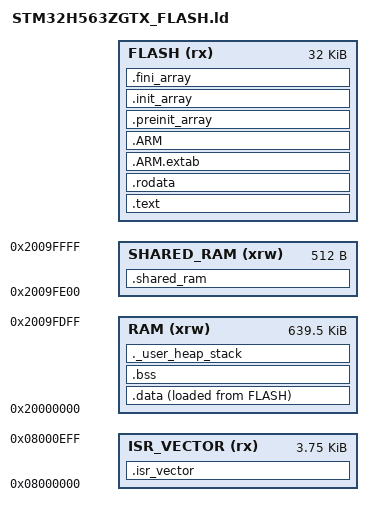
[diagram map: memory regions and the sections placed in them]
/*
******************************************************************************
**
** @file        : LinkerScript.ld
**
** @author      : Auto-generated by STM32CubeIDE
**
** @brief       : Linker script for STM32H563ZGTx Device from STM32H5 series
**                      1024KBytes FLASH
**                      640KBytes RAM
**
**                Set heap size, stack size and stack location according
**                to application requirements.
**
**                Set memory bank area and size if external memory is used
**
**  Target      : STMicroelectronics STM32
**
**  Distribution: The file is distributed as is, without any warranty
**                of any kind.
**
******************************************************************************
** @attention
**
** Copyright (c) 2025 STMicroelectronics.
** All rights reserved.
**
** This software is licensed under terms that can be found in the LICENSE file
** in the root directory of this software component.
** If no LICENSE file comes with this software, it is provided AS-IS.
**
******************************************************************************
*/

/* Entry Point */
ENTRY(Reset_Handler)

/* Highest address of the user mode stack */
_estack = ORIGIN(RAM) + LENGTH(RAM); /* end of "RAM" Ram type memory */

_Min_Heap_Size = 0x200; /* required amount of heap */
_Min_Stack_Size = 0x400; /* required amount of stack */

SECTOR_SIZE              = 0x2000;		/* 8 kB */
FLASH_MEM_SIZE           = 0x100000;	/* 1 MB */
BOOTLOADER_SIZE          = 0x00008000; 	/* 32 kB */
FLASH_BASE             	 = 0x08000000;

BOOTLOADER_START_ADDR   = FLASH_BASE + (FLASH_MEM_SIZE - BOOTLOADER_SIZE);    /* At the end of the memory */

FREE_SPACE_START        = SECTOR_SIZE;        /* The begininning of the free space */
FREE_SPACE_SIZE         = BOOTLOADER_START_ADDR - FREE_SPACE_START;   /* Size of the Free space */

RAM_BASE           = 0x20000000;
RAM_TOTAL_SIZE     = 0xA0000;      /* 640 KB */
SHARED_RAM_SIZE    = 0x200;        /* 512 B */
RAM_MAIN_SIZE      = RAM_TOTAL_SIZE - SHARED_RAM_SIZE;

PROVIDE(__free_space_start = FREE_SPACE_START);
PROVIDE(__free_space_size = FREE_SPACE_SIZE);
PROVIDE(__sector_size = SECTOR_SIZE);

/* Memories definition */
MEMORY
{
  ISR_VECTOR  (rx)   : ORIGIN = FLASH_BASE, LENGTH = 0x00000F00
  RAM         (xrw)  : ORIGIN = RAM_BASE, LENGTH = RAM_MAIN_SIZE
  SHARED_RAM  (xrw)  : ORIGIN = RAM_BASE + RAM_MAIN_SIZE, LENGTH = SHARED_RAM_SIZE
  FLASH    (rx)    	: ORIGIN = BOOTLOADER_START_ADDR,   LENGTH = BOOTLOADER_SIZE
}
/* Sections */
SECTIONS
{

  /* The startup code into "FLASH" Rom type memory */
  .isr_vector :
  {
    . = ALIGN(4);
    KEEP(*(.isr_vector)) /* Startup code */
    . = ALIGN(4);
  } >ISR_VECTOR

  /* The program code and other data into "FLASH" Rom type memory */
  .text :
  {
    . = ALIGN(4);
    *(.text)           /* .text sections (code) */
    *(.text*)          /* .text* sections (code) */
    *(.glue_7)         /* glue arm to thumb code */
    *(.glue_7t)        /* glue thumb to arm code */
    *(.eh_frame)

    KEEP (*(.init))
    KEEP (*(.fini))

    . = ALIGN(4);
    _etext = .;        /* define a global symbols at end of code */
  } >FLASH

  /* Constant data into "FLASH" Rom type memory */
  .rodata :
  {
    . = ALIGN(4);
    *(.rodata)         /* .rodata sections (constants, strings, etc.) */
    *(.rodata*)        /* .rodata* sections (constants, strings, etc.) */
    . = ALIGN(4);
  } >FLASH

  .ARM.extab (READONLY) : /* The "READONLY" keyword is only supported in GCC11 and later, remove it if using GCC10 or earlier. */
  {
    . = ALIGN(4);
    *(.ARM.extab* .gnu.linkonce.armextab.*)
    . = ALIGN(4);
  } >FLASH

  .ARM (READONLY) : /* The "READONLY" keyword is only supported in GCC11 and later, remove it if using GCC10 or earlier. */
  {
    . = ALIGN(4);
    __exidx_start = .;
    *(.ARM.exidx*)
    __exidx_end = .;
    . = ALIGN(4);
  } >FLASH

  .preinit_array (READONLY) : /* The "READONLY" keyword is only supported in GCC11 and later, remove it if using GCC10 or earlier. */
  {
    . = ALIGN(4);
    PROVIDE_HIDDEN (__preinit_array_start = .);
    KEEP (*(.preinit_array*))
    PROVIDE_HIDDEN (__preinit_array_end = .);
    . = ALIGN(4);
  } >FLASH

  .init_array (READONLY) : /* The "READONLY" keyword is only supported in GCC11 and later, remove it if using GCC10 or earlier. */
  {
    . = ALIGN(4);
    PROVIDE_HIDDEN (__init_array_start = .);
    KEEP (*(SORT(.init_array.*)))
    KEEP (*(.init_array*))
    PROVIDE_HIDDEN (__init_array_end = .);
    . = ALIGN(4);
  } >FLASH

  .fini_array (READONLY) : /* The "READONLY" keyword is only supported in GCC11 and later, remove it if using GCC10 or earlier. */
  {
    . = ALIGN(4);
    PROVIDE_HIDDEN (__fini_array_start = .);
    KEEP (*(SORT(.fini_array.*)))
    KEEP (*(.fini_array*))
    PROVIDE_HIDDEN (__fini_array_end = .);
    . = ALIGN(4);
  } >FLASH

  /* Used by the startup to initialize data */
  _sidata = LOADADDR(.data);

  /* Initialized data sections into "RAM" Ram type memory */
  .data :
  {
    . = ALIGN(4);
    _sdata = .;        /* create a global symbol at data start */
    *(.data)           /* .data sections */
    *(.data*)          /* .data* sections */
    *(.RamFunc)        /* .RamFunc sections */
    *(.RamFunc*)       /* .RamFunc* sections */

    . = ALIGN(4);
    _edata = .;        /* define a global symbol at data end */

  } >RAM AT> FLASH

  /* Uninitialized data section into "RAM" Ram type memory */
  . = ALIGN(4);
  .bss :
  {
    /* This is used by the startup in order to initialize the .bss section */
    _sbss = .;         /* define a global symbol at bss start */
    __bss_start__ = _sbss;
    *(.bss)
    *(.bss*)
    *(COMMON)

    . = ALIGN(4);
    _ebss = .;         /* define a global symbol at bss end */
    __bss_end__ = _ebss;
  } >RAM

  /* User_heap_stack section, used to check that there is enough "RAM" Ram  type memory left */
  ._user_heap_stack :
  {
    . = ALIGN(8);
    PROVIDE ( end = . );
    PROVIDE ( _end = . );
    . = . + _Min_Heap_Size;
    . = . + _Min_Stack_Size;
    . = ALIGN(8);
  } >RAM
  
  .shared_ram (NOLOAD) :
  {
    . = ALIGN(4);
    KEEP(*(.shared_ram))
  } >SHARED_RAM

  /* Remove information from the compiler libraries */
  /DISCARD/ :
  {
    libc.a ( * )
    libm.a ( * )
    libgcc.a ( * )
  }

  .ARM.attributes 0 : { *(.ARM.attributes) }
}
